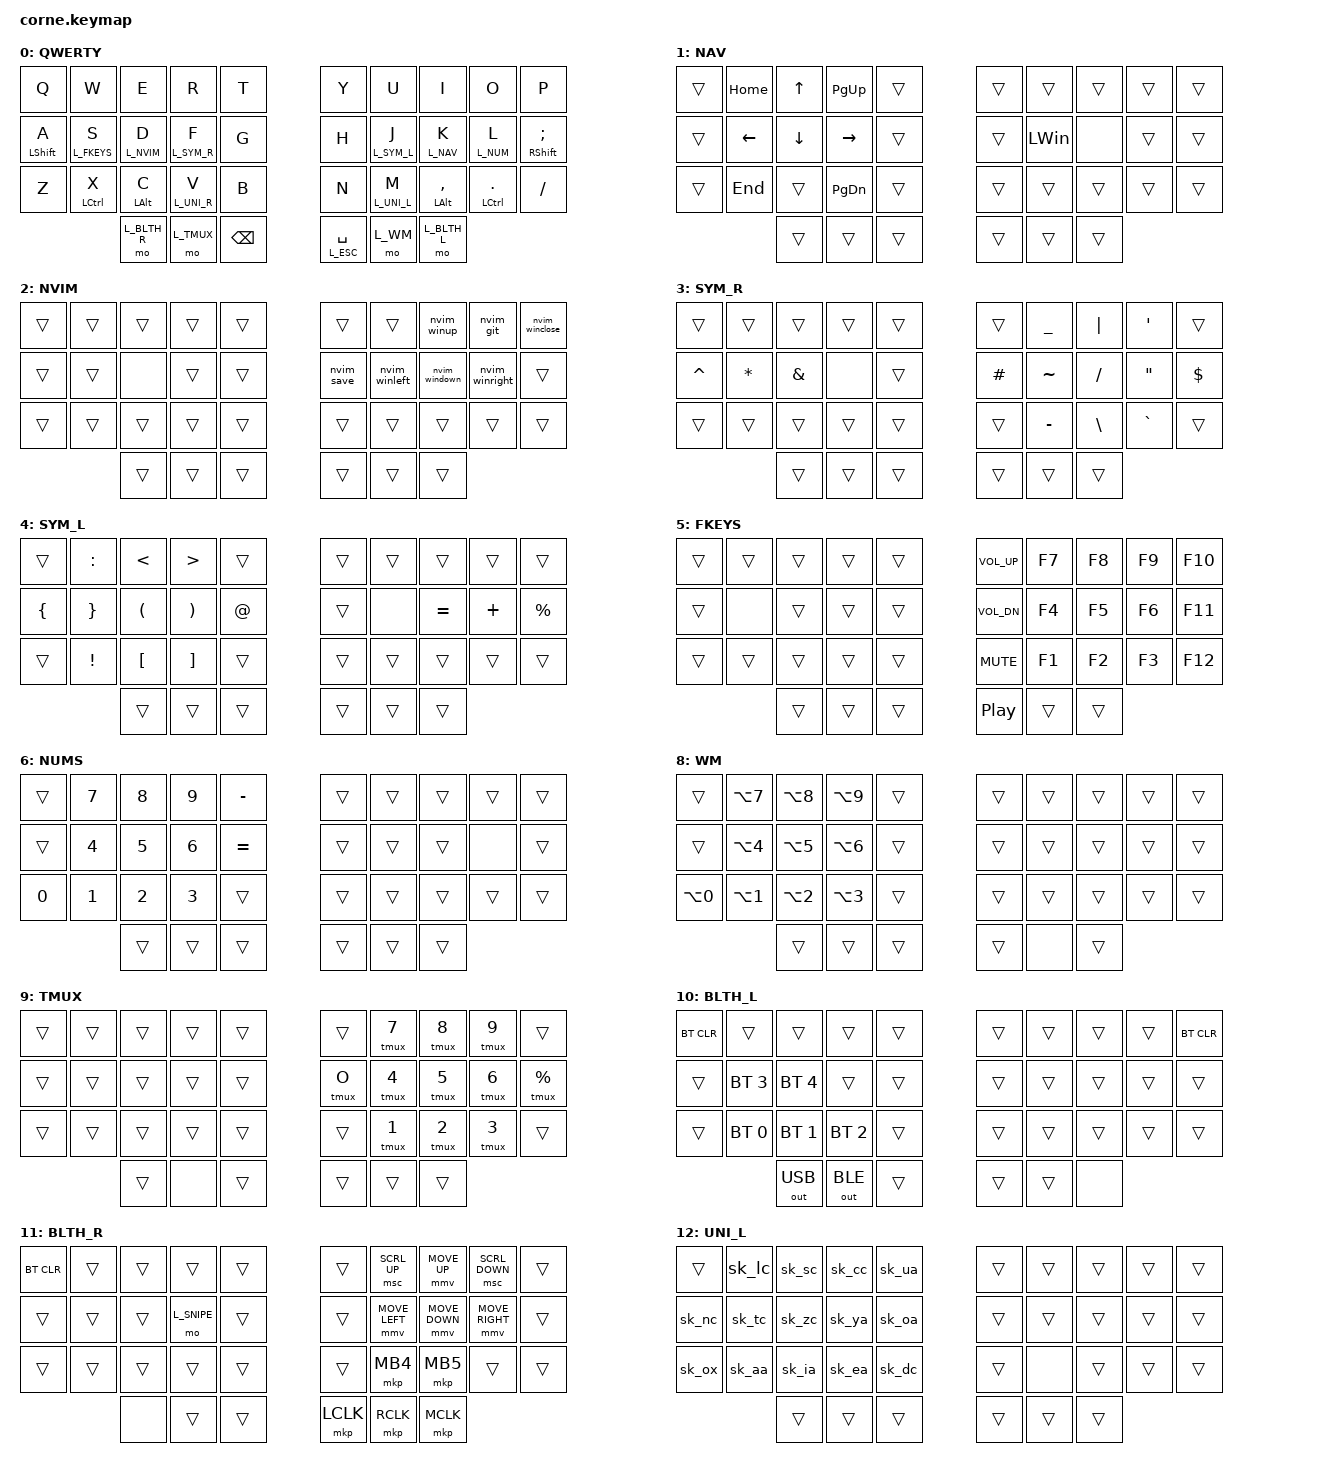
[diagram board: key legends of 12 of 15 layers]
// vim: set nowrap tw=0 fo-=t:
#include <behaviors.dtsi>
#include <input/processors.dtsi>
#include <dt-bindings/zmk/bt.h>
#include <dt-bindings/zmk/keys.h>
#include <dt-bindings/zmk/outputs.h>
#include <dt-bindings/zmk/pointing.h>
#include <dt-bindings/zmk/bt.h>

#include "zmk-helpers/helper.h"
#include "zmk-helpers/unicode-chars/currency.dtsi"
#include "zmk-helpers/unicode-chars/slovak.dtsi"
#include "zmk-helpers/unicode-chars/german.dtsi"

#define ___ &trans
#define xxx &none

#define L_QWERTY 0
#define L_NAV 1
#define L_NVIM 2
#define L_SYM_R 3
#define L_SYM_L 4
#define L_FKEYS 5
#define L_NUM 6
#define L_ESC 7
#define L_WM 8
#define L_TMUX 9
#define L_BLTH_L 10
#define L_BLTH_R 11
#define L_UNI_L 12
#define L_UNI_R 13
#define L_SNIPE 14

// tapping term definition
#define TAP_TERM_MS 180 
#define QUICK_TAP_MS 125

&lt {
  quick-tap-ms = <QUICK_TAP_MS>;
  tapping-term-ms = <TAP_TERM_MS>;
  flavor = "tap-preferred"; 
};

&mt {
  tapping-term-ms = <TAP_TERM_MS>;
  flavor = "tap-preferred"; 
};

/* unicode */
ZMK_UNICODE_SINGLE(softhyphen, N0, N0, A, D)
ZMK_UNICODE_SINGLE(nobreak, N0, N0, A, N0)
ZMK_UNICODE_SINGLE(ndash, N2, N0, N1, N3)

/ {
  chosen { zmk,matrix_transform = &five_column_transform; };

  /* behaviors { }; */

  macros {
    /* neovim */
    nvim_winleft: nvim_winleft {
      compatible = "zmk,behavior-macro";
      #binding-cells = <0>;
      bindings = <&kp LC(W) &kp H>;
    };
    nvim_windown: nvim_windown {
      compatible = "zmk,behavior-macro";
      #binding-cells = <0>;
      bindings = <&kp LC(W) &kp J>;
    };
    nvim_winup: nvim_winup {
      compatible = "zmk,behavior-macro";
      #binding-cells = <0>;
      bindings = <&kp LC(W) &kp K>;
    };
    nvim_winright: nvim_winright {
      compatible = "zmk,behavior-macro";
      #binding-cells = <0>;
      bindings = <&kp LC(W) &kp L>;
    };
    nvim_winclose: nvim_winclose {
      compatible = "zmk,behavior-macro";
      #binding-cells = <0>;
      bindings = <&kp LC(W) &kp Q>;
    };
    nvim_git: nvim_git {
      compatible = "zmk,behavior-macro";
      #binding-cells = <0>;
      bindings = <&kp LA(G)>;
    };
    nvim_save: nvim_save {
      compatible = "zmk,behavior-macro";
      #binding-cells = <0>;
      bindings = <&kp BSLH &kp BSLH>;
    };
    nvim_termesc: nvim_termesc {
      compatible = "zmk,behavior-macro";
      #binding-cells = <0>;
      bindings = <&kp LC(BACKSLASH) &kp LC(N)>;
    };

    /* tmux */
    tmux: tmux {
      compatible = "zmk,behavior-macro-one-param";
      #binding-cells = <1>;
      bindings = <&kp LC(B)>, <&macro_pause_for_release>, <&macro_param_1to1>, <&macro_tap &kp MACRO_PLACEHOLDER>;
    };
  };

  /* combos { }; */

  keymap {
    compatible = "zmk,keymap";

    qwerty {
      display-name = "QWERTY";
      bindings = <
        //╭──────────────┬──────────────┬──────────────┬──────────────┬──────────────╮     ╭──────────────┬──────────────┬──────────────┬──────────────┬──────────────╮
           &kp Q          &kp W          &kp E          &kp R          &kp T                &kp Y          &kp U          &kp I          &kp O          &kp P
        //├──────────────┼──────────────┼──────────────┼──────────────┼──────────────┤     ├──────────────┼──────────────┼──────────────┼──────────────┼──────────────┤
           &mt LSHIFT A   &lt L_FKEYS S  &lt L_NVIM D   &lt L_SYM_R F  &kp G                &kp H          &lt L_SYM_L J  &lt L_NAV K    &lt L_NUM L    &mt RSHIFT SEMI
        //├──────────────┼──────────────┼──────────────┼──────────────┼──────────────┤     ├──────────────┼──────────────┼──────────────┼──────────────┼──────────────┤
           &kp Z          &mt LCTRL X    &mt LALT C     &lt L_UNI_R V  &kp B                &kp N          &lt L_UNI_L M  &mt LALT COMMA &mt LCTRL DOT  &kp FSLH
        //╰──────────────┴──────────────┼──────────────┼──────────────┼──────────────┤     ├──────────────┼──────────────┼──────────────┼──────────────┴──────────────╯
                                         &mo L_BLTH_R   &mo L_TMUX     &kp BSPC             &lt L_ESC SPACE &mo L_WM      &mo L_BLTH_L
        //                              ╰──────────────┴──────────────┴──────────────╯     ╰──────────────┴──────────────┴──────────────╯
      >;
    };

    nav {
      display-name = "NAV";
      bindings = <
        //╭──────────────┬──────────────┬──────────────┬──────────────┬──────────────╮     ╭──────────────┬──────────────┬──────────────┬──────────────┬──────────────╮
           ___            &kp HOME       &kp UP         &kp PG_UP      ___                  ___            ___            ___            ___            ___  
        //├──────────────┼──────────────┼──────────────┼──────────────┼──────────────┤     ├──────────────┼──────────────┼──────────────┼──────────────┼──────────────┤
           ___            &kp LEFT       &kp DOWN       &kp RIGHT      ___                  ___            &kp LWIN       xxx            ___            ___         
        //├──────────────┼──────────────┼──────────────┼──────────────┼──────────────┤     ├──────────────┼──────────────┼──────────────┼──────────────┼──────────────┤
           ___            &kp END        ___            &kp PG_DN      ___                  ___            ___            ___            ___            ___          
        //╰──────────────┴──────────────┼──────────────┼──────────────┼──────────────┤     ├──────────────┼──────────────┼──────────────┼──────────────┴──────────────╯
                                         ___            ___            ___                  ___            ___            ___
        //                              ╰──────────────┴──────────────┴──────────────╯     ╰──────────────┴──────────────┴──────────────╯
      >;
    };

    nvim {
      display-name = "NVIM";
      bindings = <
        //╭──────────────┬──────────────┬──────────────┬──────────────┬──────────────╮     ╭──────────────┬──────────────┬──────────────┬──────────────┬──────────────╮
           ___            ___            ___            ___            ___                  ___            ___            &nvim_winup    &nvim_git      &nvim_winclose
        //├──────────────┼──────────────┼──────────────┼──────────────┼──────────────┤     ├──────────────┼──────────────┼──────────────┼──────────────┼──────────────┤
           ___            ___            xxx            ___            ___                  &nvim_save     &nvim_winleft  &nvim_windown  &nvim_winright ___         
        //├──────────────┼──────────────┼──────────────┼──────────────┼──────────────┤     ├──────────────┼──────────────┼──────────────┼──────────────┼──────────────┤
           ___            ___            ___            ___            ___                  ___            ___            ___            ___            ___          
        //╰──────────────┴──────────────┼──────────────┼──────────────┼──────────────┤     ├──────────────┼──────────────┼──────────────┼──────────────┴──────────────╯
                                         ___            ___            ___                  ___            ___            ___
        //                              ╰──────────────┴──────────────┴──────────────╯     ╰──────────────┴──────────────┴──────────────╯
      >;
    };

    sybmol_right {
      display-name = "SYM_R";
      bindings = <
        //╭──────────────┬──────────────┬──────────────┬──────────────┬──────────────╮     ╭──────────────┬──────────────┬──────────────┬──────────────┬──────────────╮
          ___            ___            ___            ___            ___                  ___            &kp UNDER      &kp PIPE       &kp SQT        ___  
        //├──────────────┼──────────────┼──────────────┼──────────────┼──────────────┤     ├──────────────┼──────────────┼──────────────┼──────────────┼──────────────┤
           &kp CARET      &kp STAR       &kp AMPERSAND  xxx            ___                  &kp HASH       &kp TILDE      &kp FSLH       &kp DQT        &kp DOLLAR  
        //├──────────────┼──────────────┼──────────────┼──────────────┼──────────────┤     ├──────────────┼──────────────┼──────────────┼──────────────┼──────────────┤
           ___            ___            ___            ___            ___                  ___            &kp MINUS      &kp BSLH       &kp GRAVE      ___          
        //╰──────────────┴──────────────┼──────────────┼──────────────┼──────────────┤     ├──────────────┼──────────────┼──────────────┼──────────────┴──────────────╯
                                         ___            ___            ___                  ___            ___            ___
        //                              ╰──────────────┴──────────────┴──────────────╯     ╰──────────────┴──────────────┴──────────────╯
      >;
    };

    sybmol_left {
      display-name = "SYM_L";
      bindings = <
        //╭──────────────┬──────────────┬──────────────┬──────────────┬──────────────╮     ╭──────────────┬──────────────┬──────────────┬──────────────┬──────────────╮
           ___            &kp COLON      &kp LT         &kp GT         ___                  ___            ___            ___            ___            ___  
        //├──────────────┼──────────────┼──────────────┼──────────────┼──────────────┤     ├──────────────┼──────────────┼──────────────┼──────────────┼──────────────┤
           &kp LBRC       &kp RBRC       &kp LPAR       &kp RPAR       &kp AT               ___            xxx            &kp EQUAL      &kp PLUS       &kp PERCENT 
        //├──────────────┼──────────────┼──────────────┼──────────────┼──────────────┤     ├──────────────┼──────────────┼──────────────┼──────────────┼──────────────┤
           ___            &kp EXCL       &kp LBKT       &kp RBKT       ___                  ___            ___            ___            ___            ___          
        //╰──────────────┴──────────────┼──────────────┼──────────────┼──────────────┤     ├──────────────┼──────────────┼──────────────┼──────────────┴──────────────╯
                                         ___            ___            ___                  ___            ___            ___
        //                              ╰──────────────┴──────────────┴──────────────╯     ╰──────────────┴──────────────┴──────────────╯
      >;
    };

    fkeys {
      display-name = "FKEYS";
      bindings = <
        //╭──────────────┬──────────────┬──────────────┬──────────────┬──────────────╮     ╭──────────────┬──────────────┬──────────────┬──────────────┬──────────────╮
           ___            ___            ___            ___            ___                  &kp C_VOL_UP   &kp F7         &kp F8         &kp F9         &kp F10
        //├──────────────┼──────────────┼──────────────┼──────────────┼──────────────┤     ├──────────────┼──────────────┼──────────────┼──────────────┼──────────────┤
           ___            xxx            ___            ___            ___                  &kp C_VOL_DN   &kp F4         &kp F5         &kp F6         &kp F11     
        //├──────────────┼──────────────┼──────────────┼──────────────┼──────────────┤     ├──────────────┼──────────────┼──────────────┼──────────────┼──────────────┤
           ___            ___            ___            ___            ___                  &kp C_MUTE     &kp F1         &kp F2         &kp F3         &kp F12      
        //╰──────────────┴──────────────┼──────────────┼──────────────┼──────────────┤     ├──────────────┼──────────────┼──────────────┼──────────────┴──────────────╯
                                         ___            ___            ___                  &kp C_PP       ___            ___
        //                              ╰──────────────┴──────────────┴──────────────╯     ╰──────────────┴──────────────┴──────────────╯
      >;
    };

    nums {
      display-name = "NUMS";
      bindings = <
        //╭──────────────┬──────────────┬──────────────┬──────────────┬──────────────╮     ╭──────────────┬──────────────┬──────────────┬──────────────┬──────────────╮
           ___            &kp N7         &kp N8         &kp N9         &kp MINUS            ___            ___            ___            ___            ___  
        //├──────────────┼──────────────┼──────────────┼──────────────┼──────────────┤     ├──────────────┼──────────────┼──────────────┼──────────────┼──────────────┤
           ___            &kp N4         &kp N5         &kp N6         &kp EQUAL            ___            ___            ___            xxx            ___         
        //├──────────────┼──────────────┼──────────────┼──────────────┼──────────────┤     ├──────────────┼──────────────┼──────────────┼──────────────┼──────────────┤
           &kp N0         &kp N1         &kp N2         &kp N3         ___                  ___            ___            ___            ___            ___          
        //╰──────────────┴──────────────┼──────────────┼──────────────┼──────────────┤     ├──────────────┼──────────────┼──────────────┼──────────────┴──────────────╯
                                         ___            ___            ___                  ___            ___            ___
        //                              ╰──────────────┴──────────────┴──────────────╯     ╰──────────────┴──────────────┴──────────────╯
      >;
    };

    esc {
      display-name = "ESC";
      bindings = <
        //╭──────────────┬──────────────┬──────────────┬──────────────┬──────────────╮     ╭──────────────┬──────────────┬──────────────┬──────────────┬──────────────╮
           &kp CAPS       ___            &nvim_termesc  &kp ESC        ___                  &kp LC(PSCRN)  &kp LC(LS(PSCRN)) &kp LC(LA(LS(PSCRN))) ___  ___
        //├──────────────┼──────────────┼──────────────┼──────────────┼──────────────┤     ├──────────────┼──────────────┼──────────────┼──────────────┼──────────────┤
           &caps_word     ___            &kp DEL        &kp ENTER      ___                  &kp LA(PSCRN)  &kp LS(PSCRN)  ___            ___            ___
        //├──────────────┼──────────────┼──────────────┼──────────────┼──────────────┤     ├──────────────┼──────────────┼──────────────┼──────────────┼──────────────┤
           ___            ___            ___            ___            ___                  ___            ___            ___            ___            ___          
        //╰──────────────┴──────────────┼──────────────┼──────────────┼──────────────┤     ├──────────────┼──────────────┼──────────────┼──────────────┴──────────────╯
                                         ___            ___            &kp TAB              xxx            &kp LG(L)      ___
        //                              ╰──────────────┴──────────────┴──────────────╯     ╰──────────────┴──────────────┴──────────────╯
      >;
    };

    wm {
      display-name = "WM";
      bindings = <
        //╭──────────────┬──────────────┬──────────────┬──────────────┬──────────────╮     ╭──────────────┬──────────────┬──────────────┬──────────────┬──────────────╮
           ___            &kp LA(N7)     &kp LA(N8)     &kp LA(N9)     ___                  ___            ___            ___            ___            ___  
        //├──────────────┼──────────────┼──────────────┼──────────────┼──────────────┤     ├──────────────┼──────────────┼──────────────┼──────────────┼──────────────┤
           ___            &kp LA(N4)     &kp LA(N5)     &kp LA(N6)     ___                  ___            ___            ___            ___            ___         
        //├──────────────┼──────────────┼──────────────┼──────────────┼──────────────┤     ├──────────────┼──────────────┼──────────────┼──────────────┼──────────────┤
           &kp LA(N0)     &kp LA(N1)     &kp LA(N2)     &kp LA(N3)     ___                  ___            ___            ___            ___            ___          
        //╰──────────────┴──────────────┼──────────────┼──────────────┼──────────────┤     ├──────────────┼──────────────┼──────────────┼──────────────┴──────────────╯
                                         ___            ___            ___                  ___            xxx            ___
        //                              ╰──────────────┴──────────────┴──────────────╯     ╰──────────────┴──────────────┴──────────────╯
      >;
    };

    tmux {
      display-name = "TMUX";
      bindings = <
        //╭──────────────┬──────────────┬──────────────┬──────────────┬──────────────╮     ╭──────────────┬──────────────┬──────────────┬──────────────┬──────────────╮
           ___            ___            ___            ___            ___                  ___            &tmux N7       &tmux N8       &tmux N9        ___  
        //├──────────────┼──────────────┼──────────────┼──────────────┼──────────────┤     ├──────────────┼──────────────┼──────────────┼──────────────┼──────────────┤
           ___            ___            ___            ___            ___                  &tmux O        &tmux N4       &tmux N5       &tmux N6       &tmux PERCENT
        //├──────────────┼──────────────┼──────────────┼──────────────┼──────────────┤     ├──────────────┼──────────────┼──────────────┼──────────────┼──────────────┤
           ___            ___            ___            ___            ___                  ___            &tmux N1       &tmux N2       &tmux N3        ___          
        //╰──────────────┴──────────────┼──────────────┼──────────────┼──────────────┤     ├──────────────┼──────────────┼──────────────┼──────────────┴──────────────╯
                                         ___            xxx            ___                  ___            ___            ___
        //                              ╰──────────────┴──────────────┴──────────────╯     ╰──────────────┴──────────────┴──────────────╯
      >;
    };
     
    blth_l {
      display-name = "BLTH_L";
      bindings = <
        //╭──────────────┬──────────────┬──────────────┬──────────────┬──────────────╮     ╭──────────────┬──────────────┬──────────────┬──────────────┬──────────────╮
           &bt BT_CLR     ___            ___            ___            ___                  ___            ___            ___            ___            &bt BT_CLR 
        //├──────────────┼──────────────┼──────────────┼──────────────┼──────────────┤     ├──────────────┼──────────────┼──────────────┼──────────────┼──────────────┤
           ___            &bt BT_SEL 3   &bt BT_SEL 4   ___            ___                  ___            ___            ___            ___            ___         
        //├──────────────┼──────────────┼──────────────┼──────────────┼──────────────┤     ├──────────────┼──────────────┼──────────────┼──────────────┼──────────────┤
           ___            &bt BT_SEL 0   &bt BT_SEL 1   &bt BT_SEL 2   ___                  ___            ___            ___            ___            ___          
        //╰──────────────┴──────────────┼──────────────┼──────────────┼──────────────┤     ├──────────────┼──────────────┼──────────────┼──────────────┴──────────────╯
                                         &out OUT_USB   &out OUT_BLE   ___                  ___            ___            xxx
        //                              ╰──────────────┴──────────────┴──────────────╯     ╰──────────────┴──────────────┴──────────────╯
      >;
    };

    blth_r {
      display-name = "BLTH_R";
      bindings = <
        //╭──────────────┬──────────────┬──────────────┬──────────────┬──────────────╮     ╭──────────────┬──────────────┬──────────────┬──────────────┬──────────────╮
           &bt BT_CLR     ___            ___            ___            ___                  ___            &msc SCRL_UP   &mmv MOVE_UP   &msc SCRL_DOWN ___         
        //├──────────────┼──────────────┼──────────────┼──────────────┼──────────────┤     ├──────────────┼──────────────┼──────────────┼──────────────┼──────────────┤
           ___            ___            ___            &mo L_SNIPE    ___                  ___            &mmv MOVE_LEFT &mmv MOVE_DOWN &mmv MOVE_RIGHT ___       
        //├──────────────┼──────────────┼──────────────┼──────────────┼──────────────┤     ├──────────────┼──────────────┼──────────────┼──────────────┼──────────────┤
           ___            ___            ___            ___            ___                  ___            &mkp MB4       &mkp MB5       ___            ___          
        //╰──────────────┴──────────────┼──────────────┼──────────────┼──────────────┤     ├──────────────┼──────────────┼──────────────┼──────────────┴──────────────╯
                                         xxx            ___            ___                  &mkp LCLK      &mkp RCLK      &mkp MCLK
        //                              ╰──────────────┴──────────────┴──────────────╯     ╰──────────────┴──────────────┴──────────────╯
      >;
    };

    uni_l {
      display-name = "UNI_L";
      bindings = <
        //╭──────────────┬──────────────┬──────────────┬──────────────┬──────────────╮     ╭──────────────┬──────────────┬──────────────┬──────────────┬──────────────╮
           ___            &sk_lc         &sk_sc         &sk_cc         &sk_ua               ___            ___            ___            ___            ___  
        //├──────────────┼──────────────┼──────────────┼──────────────┼──────────────┤     ├──────────────┼──────────────┼──────────────┼──────────────┼──────────────┤
           &sk_nc         &sk_tc         &sk_zc         &sk_ya         &sk_oa               ___            ___            ___            ___            ___         
        //├──────────────┼──────────────┼──────────────┼──────────────┼──────────────┤     ├──────────────┼──────────────┼──────────────┼──────────────┼──────────────┤
           &sk_ox         &sk_aa         &sk_ia         &sk_ea         &sk_dc               ___            xxx            ___            ___            ___          
        //╰──────────────┴──────────────┼──────────────┼──────────────┼──────────────┤     ├──────────────┼──────────────┼──────────────┼──────────────┴──────────────╯
                                         ___            ___            ___                  ___            ___            ___
        //                              ╰──────────────┴──────────────┴──────────────╯     ╰──────────────┴──────────────┴──────────────╯
      >;
    };

    uni_r {
      display-name = "UNI_R";
      bindings = <
        //╭──────────────┬──────────────┬──────────────┬──────────────┬──────────────╮     ╭──────────────┬──────────────┬──────────────┬──────────────┬──────────────╮
           ___            ___            ___            ___            ___                  ___            ___            ___            ___            &curr_euro  
        //├──────────────┼──────────────┼──────────────┼──────────────┼──────────────┤     ├──────────────┼──────────────┼──────────────┼──────────────┼──────────────┤
           ___            ___            ___            ___            ___                  ___            &de_ae         &de_ue         &de_oe         &de_eszett
        //├──────────────┼──────────────┼──────────────┼──────────────┼──────────────┤     ├──────────────┼──────────────┼──────────────┼──────────────┼──────────────┤
           ___            ___            ___            xxx            ___                  ___            &softhyphen    &nobreak       &ndash         ___          
        //╰──────────────┴──────────────┼──────────────┼──────────────┼──────────────┤     ├──────────────┼──────────────┼──────────────┼──────────────┴──────────────╯
                                         ___            ___            ___                  ___            ___            ___
        //                              ╰──────────────┴──────────────┴──────────────╯     ╰──────────────┴──────────────┴──────────────╯
      >;
    };

    /* held on top of BLTH_R: slows mouse movement for precise targeting */
    snipe {
      display-name = "SNIPE";
      bindings = <
        //╭──────────────┬──────────────┬──────────────┬──────────────┬──────────────╮     ╭──────────────┬──────────────┬──────────────┬──────────────┬──────────────╮
           ___            ___            ___            ___            ___                  ___            ___            ___            ___            ___  
        //├──────────────┼──────────────┼──────────────┼──────────────┼──────────────┤     ├──────────────┼──────────────┼──────────────┼──────────────┼──────────────┤
           ___            ___            ___            xxx            ___                  ___            ___            ___            ___            ___         
        //├──────────────┼──────────────┼──────────────┼──────────────┼──────────────┤     ├──────────────┼──────────────┼──────────────┼──────────────┼──────────────┤
           ___            ___            ___            ___            ___                  ___            ___            ___            ___            ___          
        //╰──────────────┴──────────────┼──────────────┼──────────────┼──────────────┤     ├──────────────┼──────────────┼──────────────┼──────────────┴──────────────╯
                                         xxx            ___            ___                  ___            ___            ___
        //                              ╰──────────────┴──────────────┴──────────────╯     ╰──────────────┴──────────────┴──────────────╯
      >;
    };
  };
};

/* mouse movement at 1/4 speed while SNIPE is active */
&mmv_input_listener {
  snipe {
    layers = <L_SNIPE>;
    input-processors = <&zip_xy_scaler 1 4>;
  };
};

/*
        //╭──────────────┬──────────────┬──────────────┬──────────────┬──────────────╮     ╭──────────────┬──────────────┬──────────────┬──────────────┬──────────────╮
           ___            ___            ___            ___            ___                  ___            ___            ___            ___            ___  
        //├──────────────┼──────────────┼──────────────┼──────────────┼──────────────┤     ├──────────────┼──────────────┼──────────────┼──────────────┼──────────────┤
           ___            ___            ___            ___            ___                  ___            ___            ___            ___            ___         
        //├──────────────┼──────────────┼──────────────┼──────────────┼──────────────┤     ├──────────────┼──────────────┼──────────────┼──────────────┼──────────────┤
           ___            ___            ___            ___            ___                  ___            ___            ___            ___            ___          
        //╰──────────────┴──────────────┼──────────────┼──────────────┼──────────────┤     ├──────────────┼──────────────┼──────────────┼──────────────┴──────────────╯
                                         ___            ___            ___                  ___            ___            ___
        //                              ╰──────────────┴──────────────┴──────────────╯     ╰──────────────┴──────────────┴──────────────╯
*/
